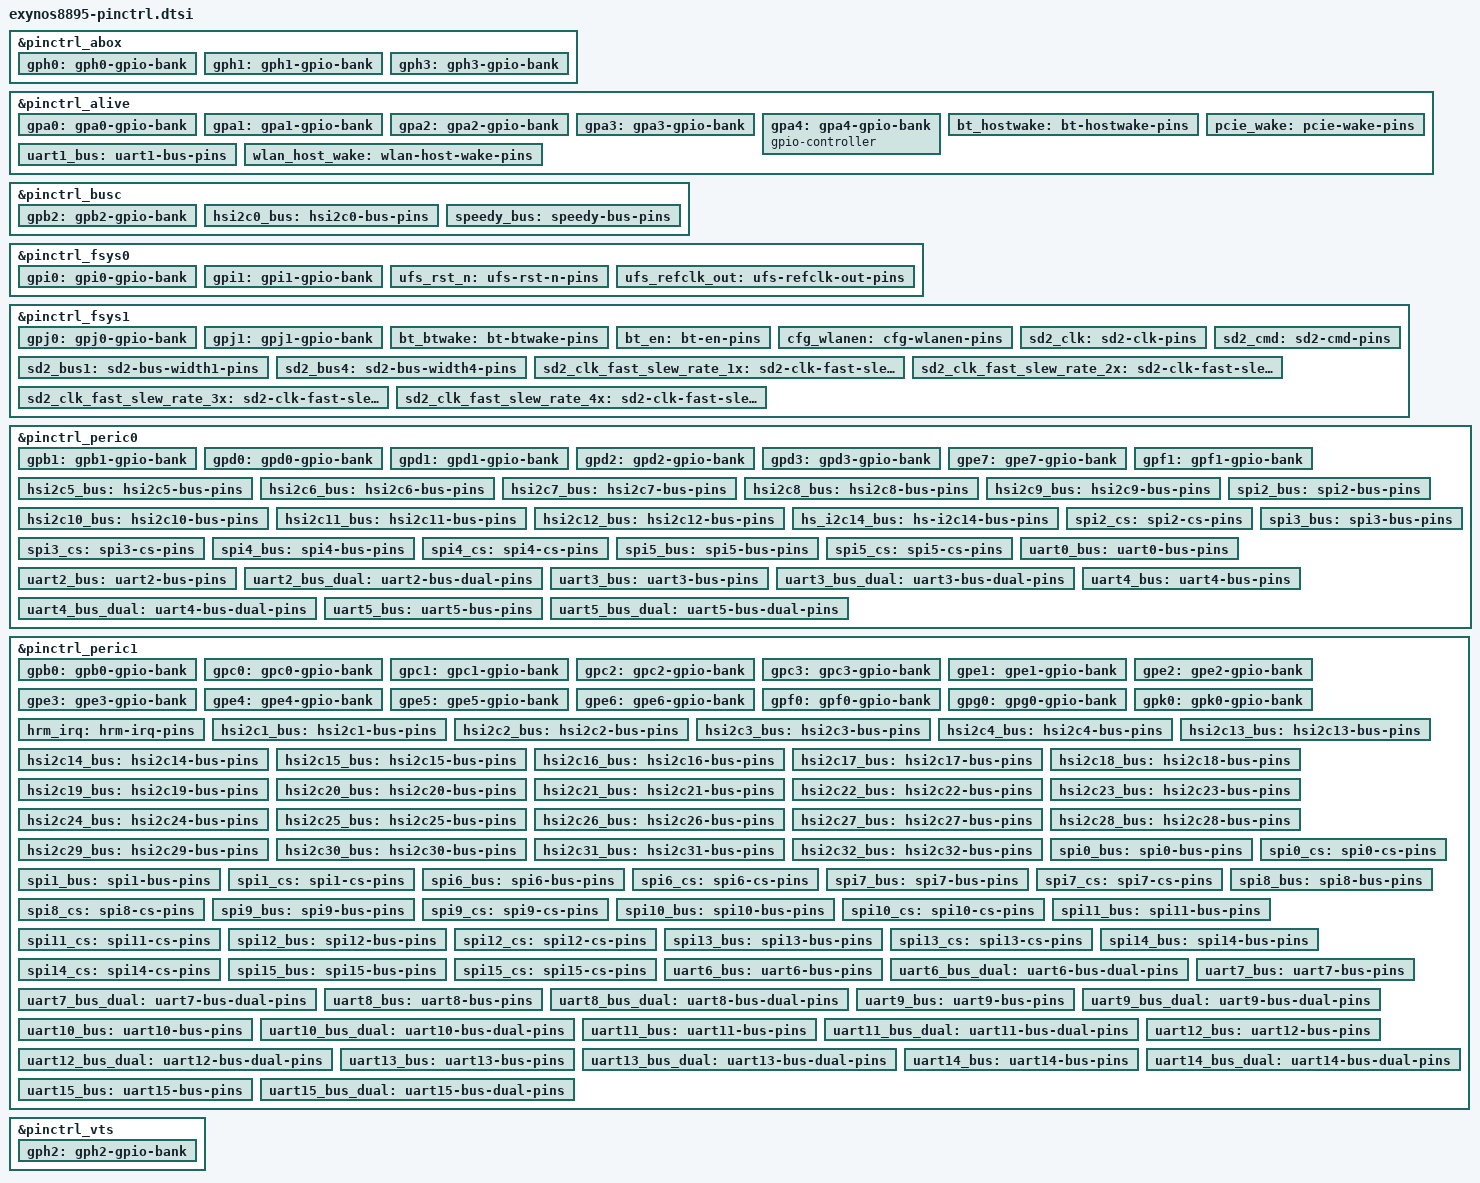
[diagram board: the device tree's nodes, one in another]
// SPDX-License-Identifier: GPL-2.0 OR BSD-3-Clause
/*
 * Samsung's Exynos 8895 SoC pin-mux and pin-config device tree source
 *
 * Copyright (c) 2024, Ivaylo Ivanov <ivo.ivanov.ivanov1@gmail.com>
 */

#include <dt-bindings/interrupt-controller/arm-gic.h>
#include "exynos-pinctrl.h"

&pinctrl_abox {
	gph0: gph0-gpio-bank {
		gpio-controller;
		#gpio-cells = <2>;

		interrupt-controller;
		#interrupt-cells = <2>;
	};

	gph1: gph1-gpio-bank {
		gpio-controller;
		#gpio-cells = <2>;

		interrupt-controller;
		#interrupt-cells = <2>;
	};

	gph3: gph3-gpio-bank {
		gpio-controller;
		#gpio-cells = <2>;

		interrupt-controller;
		#interrupt-cells = <2>;
	};
};

&pinctrl_alive {
	gpa0: gpa0-gpio-bank {
		gpio-controller;
		#gpio-cells = <2>;

		interrupt-controller;
		#interrupt-cells = <2>;
		interrupt-parent = <&gic>;
		interrupts = <GIC_SPI 0 IRQ_TYPE_LEVEL_HIGH>,
			     <GIC_SPI 1 IRQ_TYPE_LEVEL_HIGH>,
			     <GIC_SPI 2 IRQ_TYPE_LEVEL_HIGH>,
			     <GIC_SPI 3 IRQ_TYPE_LEVEL_HIGH>,
			     <GIC_SPI 4 IRQ_TYPE_LEVEL_HIGH>,
			     <GIC_SPI 5 IRQ_TYPE_LEVEL_HIGH>,
			     <GIC_SPI 6 IRQ_TYPE_LEVEL_HIGH>,
			     <GIC_SPI 7 IRQ_TYPE_LEVEL_HIGH>;
	};

	gpa1: gpa1-gpio-bank {
		gpio-controller;
		#gpio-cells = <2>;

		interrupt-controller;
		#interrupt-cells = <2>;
		interrupt-parent = <&gic>;
		interrupts = <GIC_SPI 8 IRQ_TYPE_LEVEL_HIGH>,
			     <GIC_SPI 9 IRQ_TYPE_LEVEL_HIGH>,
			     <GIC_SPI 10 IRQ_TYPE_LEVEL_HIGH>,
			     <GIC_SPI 11 IRQ_TYPE_LEVEL_HIGH>,
			     <GIC_SPI 12 IRQ_TYPE_LEVEL_HIGH>,
			     <GIC_SPI 13 IRQ_TYPE_LEVEL_HIGH>,
			     <GIC_SPI 14 IRQ_TYPE_LEVEL_HIGH>,
			     <GIC_SPI 15 IRQ_TYPE_LEVEL_HIGH>;
	};

	gpa2: gpa2-gpio-bank {
		gpio-controller;
		#gpio-cells = <2>;

		interrupt-controller;
		#interrupt-cells = <2>;
	};

	gpa3: gpa3-gpio-bank {
		gpio-controller;
		#gpio-cells = <2>;

		interrupt-controller;
		#interrupt-cells = <2>;
	};

	gpa4: gpa4-gpio-bank {
		gpio-controller;
		#gpio-cells = <2>;
	};

	bt_hostwake: bt-hostwake-pins {
		samsung,pins = "gpa2-3";
		samsung,pin-function = <EXYNOS_PIN_FUNC_INPUT>;
		samsung,pin-pud = <EXYNOS_PIN_PULL_NONE>;
		samsung,pin-con-pdn = <EXYNOS_PIN_PDN_INPUT>;
		samsung,pin-pud-pdn = <EXYNOS_PIN_PULL_NONE>;
	};

	pcie_wake: pcie-wake-pins {
		samsung,pins = "gpa3-3";
		samsung,pin-function = <EXYNOS_PIN_FUNC_INPUT>;
		samsung,pin-pud = <EXYNOS_PIN_PULL_NONE>;
	};

	uart1_bus: uart1-bus-pins {
		samsung,pins = "gpa4-4", "gpa4-3", "gpa4-2", "gpa4-1";
		samsung,pin-function = <EXYNOS_PIN_FUNC_2>;
		samsung,pin-pud = <EXYNOS_PIN_PULL_NONE>;
	};

	wlan_host_wake: wlan-host-wake-pins {
		  samsung,pins = "gpa0-7";
		  samsung,pin-function = <EXYNOS_PIN_FUNC_EINT>;
		  samsung,pin-pud = <EXYNOS_PIN_PULL_DOWN>;
		  samsung,pin-con-pdn = <EXYNOS_PIN_PDN_PREV>;
		  samsung,pin-pud-pdn = <EXYNOS_PIN_PULL_DOWN>;
	};
};

&pinctrl_busc {
	gpb2: gpb2-gpio-bank {
		gpio-controller;
		#gpio-cells = <2>;

		interrupt-controller;
		#interrupt-cells = <2>;
	};

	hsi2c0_bus: hsi2c0-bus-pins {
		samsung,pins = "gpb2-1", "gpb2-0";
		samsung,pin-function = <EXYNOS_PIN_FUNC_3>;
		samsung,pin-pud = <EXYNOS_PIN_PULL_UP>;
		samsung,pin-drv = <EXYNOS7_PIN_DRV_LV1>;
	};

	speedy_bus: speedy-bus-pins {
		samsung,pins = "gpb2-0";
		samsung,pin-function = <EXYNOS_PIN_FUNC_2>;
		samsung,pin-con-pdn = <EXYNOS_PIN_PDN_PREV>;
		samsung,pin-pud = <EXYNOS_PIN_PULL_UP>;
		samsung,pin-drv = <EXYNOS7_PIN_DRV_LV1>;
	};
};

&pinctrl_fsys0 {
	gpi0: gpi0-gpio-bank {
		gpio-controller;
		#gpio-cells = <2>;

		interrupt-controller;
		#interrupt-cells = <2>;
	};

	gpi1: gpi1-gpio-bank {
		gpio-controller;
		#gpio-cells = <2>;

		interrupt-controller;
		#interrupt-cells = <2>;
	};

	ufs_rst_n: ufs-rst-n-pins {
		samsung,pins = "gpi0-1";
		samsung,pin-function = <EXYNOS_PIN_FUNC_3>;
		samsung,pin-pud = <EXYNOS_PIN_PULL_NONE>;
		samsung,pin-con-pdn = <EXYNOS_PIN_PDN_PREV>;
	};

	ufs_refclk_out: ufs-refclk-out-pins {
		samsung,pins = "gpi0-0";
		samsung,pin-function = <EXYNOS_PIN_FUNC_3>;
		samsung,pin-pud = <EXYNOS_PIN_PULL_NONE>;
		samsung,pin-con-pdn = <EXYNOS_PIN_PDN_PREV>;
	};
};

&pinctrl_fsys1 {
	gpj0: gpj0-gpio-bank {
		gpio-controller;
		#gpio-cells = <2>;

		interrupt-controller;
		#interrupt-cells = <2>;
	};

	gpj1: gpj1-gpio-bank {
		gpio-controller;
		#gpio-cells = <2>;

		interrupt-controller;
		#interrupt-cells = <2>;
	};

	bt_btwake: bt-btwake-pins {
		samsung,pins = "gpj1-4";
		samsung,pin-function = <EXYNOS_PIN_FUNC_OUTPUT>;
		samsung,pin-pud = <EXYNOS_PIN_PULL_NONE>;
		samsung,pin-con-pdn = <EXYNOS_PIN_PDN_PREV>;
		samsung,pin-pud-pdn = <EXYNOS_PIN_PULL_NONE>;
	};

	bt_en: bt-en-pins {
		samsung,pins = "gpj1-7";
		samsung,pin-function = <EXYNOS_PIN_FUNC_OUTPUT>;
		samsung,pin-pud = <EXYNOS_PIN_PULL_NONE>;
		samsung,pin-con-pdn = <EXYNOS_PIN_PDN_PREV>;
		samsung,pin-pud-pdn = <EXYNOS_PIN_PULL_NONE>;
	};

	cfg_wlanen: cfg-wlanen-pins {
		samsung,pins = "gpj1-3";
		samsung,pin-function = <EXYNOS_PIN_FUNC_OUTPUT>;
		samsung,pin-pud = <EXYNOS_PIN_PULL_NONE>;
		samsung,pin-drv = <EXYNOS7_PIN_DRV_LV4>;
		samsung,pin-con-pdn = <EXYNOS_PIN_PDN_PREV>;
	};

	sd2_clk: sd2-clk-pins {
		samsung,pins = "gpj0-0";
		samsung,pin-function = <EXYNOS_PIN_FUNC_2>;
		samsung,pin-pud = <EXYNOS_PIN_PULL_NONE>;
		samsung,pin-drv = <EXYNOS7_PIN_DRV_LV2>;
	};

	sd2_cmd: sd2-cmd-pins {
		samsung,pins = "gpj0-1";
		samsung,pin-function = <EXYNOS_PIN_FUNC_2>;
		samsung,pin-pud = <EXYNOS_PIN_PULL_NONE>;
		samsung,pin-drv = <EXYNOS7_PIN_DRV_LV3>;
	};

	sd2_bus1: sd2-bus-width1-pins {
		samsung,pins = "gpj0-2";
		samsung,pin-function = <EXYNOS_PIN_FUNC_2>;
		samsung,pin-pud = <EXYNOS_PIN_PULL_NONE>;
		samsung,pin-drv = <EXYNOS7_PIN_DRV_LV3>;
	};

	sd2_bus4: sd2-bus-width4-pins {
		samsung,pins = "gpj0-3", "gpj0-4", "gpj0-5";
		samsung,pin-function = <EXYNOS_PIN_FUNC_2>;
		samsung,pin-pud = <EXYNOS_PIN_PULL_NONE>;
		samsung,pin-drv = <EXYNOS7_PIN_DRV_LV3>;
	};

	/* For Drive strength swapping */
	sd2_clk_fast_slew_rate_1x: sd2-clk-fast-slew-rate-1x-pins {
		samsung,pins = "gpj0-0";
		samsung,pin-function = <EXYNOS_PIN_FUNC_2>;
		samsung,pin-pud = <EXYNOS_PIN_PULL_NONE>;
		samsung,pin-drv = <EXYNOS7_PIN_DRV_LV1>;
	};

	sd2_clk_fast_slew_rate_2x: sd2-clk-fast-slew-rate-2x-pins {
		samsung,pins = "gpj0-0";
		samsung,pin-function = <EXYNOS_PIN_FUNC_2>;
		samsung,pin-pud = <EXYNOS_PIN_PULL_NONE>;
		samsung,pin-drv = <EXYNOS7_PIN_DRV_LV3>;
	};

	sd2_clk_fast_slew_rate_3x: sd2-clk-fast-slew-rate-3x-pins {
		samsung,pins = "gpj0-0";
		samsung,pin-function = <EXYNOS_PIN_FUNC_2>;
		samsung,pin-pud = <EXYNOS_PIN_PULL_NONE>;
		samsung,pin-drv = <EXYNOS7_PIN_DRV_LV2>;
	};

	sd2_clk_fast_slew_rate_4x: sd2-clk-fast-slew-rate-4x-pins {
		samsung,pins = "gpj0-0";
		samsung,pin-function = <EXYNOS_PIN_FUNC_2>;
		samsung,pin-pud = <EXYNOS_PIN_PULL_NONE>;
		samsung,pin-drv = <EXYNOS7_PIN_DRV_LV4>;
	};
};

&pinctrl_peric0 {
	gpb1: gpb1-gpio-bank {
		gpio-controller;
		#gpio-cells = <2>;

		interrupt-controller;
		#interrupt-cells = <2>;
	};

	gpd0: gpd0-gpio-bank {
		gpio-controller;
		#gpio-cells = <2>;

		interrupt-controller;
		#interrupt-cells = <2>;
	};

	gpd1: gpd1-gpio-bank {
		gpio-controller;
		#gpio-cells = <2>;

		interrupt-controller;
		#interrupt-cells = <2>;
	};

	gpd2: gpd2-gpio-bank {
		gpio-controller;
		#gpio-cells = <2>;

		interrupt-controller;
		#interrupt-cells = <2>;
	};

	gpd3: gpd3-gpio-bank {
		gpio-controller;
		#gpio-cells = <2>;

		interrupt-controller;
		#interrupt-cells = <2>;
	};

	gpe7: gpe7-gpio-bank {
		gpio-controller;
		#gpio-cells = <2>;

		interrupt-controller;
		#interrupt-cells = <2>;
	};

	gpf1: gpf1-gpio-bank {
		gpio-controller;
		#gpio-cells = <2>;

		interrupt-controller;
		#interrupt-cells = <2>;
	};

	hsi2c5_bus: hsi2c5-bus-pins {
		samsung,pins = "gpd1-1", "gpd1-0";
		samsung,pin-function = <EXYNOS_PIN_FUNC_2>;
		samsung,pin-pud = <EXYNOS_PIN_PULL_NONE>;
		samsung,pin-drv = <EXYNOS7_PIN_DRV_LV1>;
	};

	hsi2c6_bus: hsi2c6-bus-pins {
		samsung,pins = "gpd1-3", "gpd1-2";
		samsung,pin-function = <EXYNOS_PIN_FUNC_2>;
		samsung,pin-pud = <EXYNOS_PIN_PULL_NONE>;
		samsung,pin-drv = <EXYNOS7_PIN_DRV_LV1>;
	};

	hsi2c7_bus: hsi2c7-bus-pins {
		samsung,pins = "gpd1-5", "gpd1-4";
		samsung,pin-function = <EXYNOS_PIN_FUNC_2>;
		samsung,pin-pud = <EXYNOS_PIN_PULL_NONE>;
		samsung,pin-drv = <EXYNOS7_PIN_DRV_LV1>;
	};

	hsi2c8_bus: hsi2c8-bus-pins {
		samsung,pins = "gpd1-7", "gpd1-6";
		samsung,pin-function = <EXYNOS_PIN_FUNC_2>;
		samsung,pin-pud = <EXYNOS_PIN_PULL_NONE>;
		samsung,pin-drv = <EXYNOS7_PIN_DRV_LV1>;
	};

	hsi2c9_bus: hsi2c9-bus-pins {
		samsung,pins = "gpd2-1", "gpd2-0";
		samsung,pin-function = <EXYNOS_PIN_FUNC_2>;
		samsung,pin-pud = <EXYNOS_PIN_PULL_NONE>;
		samsung,pin-drv = <EXYNOS7_PIN_DRV_LV1>;
	};

	hsi2c10_bus: hsi2c10-bus-pins {
		samsung,pins = "gpd2-3", "gpd2-2";
		samsung,pin-function = <EXYNOS_PIN_FUNC_2>;
		samsung,pin-pud = <EXYNOS_PIN_PULL_NONE>;
		samsung,pin-drv = <EXYNOS7_PIN_DRV_LV1>;
	};

	hsi2c11_bus: hsi2c11-bus-pins {
		samsung,pins = "gpd3-1", "gpd3-0";
		samsung,pin-function = <EXYNOS_PIN_FUNC_2>;
		samsung,pin-pud = <EXYNOS_PIN_PULL_NONE>;
		samsung,pin-drv = <EXYNOS7_PIN_DRV_LV1>;
	};

	hsi2c12_bus: hsi2c12-bus-pins {
		samsung,pins = "gpd3-3", "gpd3-2";
		samsung,pin-function = <EXYNOS_PIN_FUNC_2>;
		samsung,pin-pud = <EXYNOS_PIN_PULL_NONE>;
		samsung,pin-drv = <EXYNOS7_PIN_DRV_LV1>;
	};

	hs_i2c14_bus: hs-i2c14-bus-pins {
		samsung,pins = "gpe6-3", "gpe6-2";
		samsung,pin-function = <EXYNOS_PIN_FUNC_2>;
		samsung,pin-pud = <EXYNOS_PIN_PULL_NONE>;
		samsung,pin-drv = <EXYNOS7_PIN_DRV_LV2>;
	};

	spi2_bus: spi2-bus-pins {
		samsung,pins = "gpd1-3", "gpd1-2", "gpd1-1", "gpd1-0";
		samsung,pin-function = <EXYNOS_PIN_FUNC_2>;
		samsung,pin-pud = <EXYNOS_PIN_PULL_UP>;
		samsung,pin-drv = <EXYNOS7_PIN_DRV_LV2>;
	};

	spi2_cs: spi2-cs-pins {
		samsung,pins = "gpd1-2";
		samsung,pin-function = <EXYNOS_PIN_FUNC_OUTPUT>;
		samsung,pin-pud = <EXYNOS_PIN_PULL_UP>;
		samsung,pin-drv = <EXYNOS7_PIN_DRV_LV1>;
	};

	spi3_bus: spi3-bus-pins {
		samsung,pins = "gpd1-7", "gpd1-5", "gpd1-4";
		samsung,pin-function = <EXYNOS_PIN_FUNC_2>;
		samsung,pin-pud = <EXYNOS_PIN_PULL_NONE>;
		samsung,pin-drv = <EXYNOS7_PIN_DRV_LV1>;
	};

	spi3_cs: spi3-cs-pins {
		samsung,pins = "gpd1-6";
		samsung,pin-function = <EXYNOS_PIN_FUNC_OUTPUT>;
		samsung,pin-pud = <EXYNOS_PIN_PULL_UP>;
		samsung,pin-drv = <EXYNOS7_PIN_DRV_LV1>;
	};

	spi4_bus: spi4-bus-pins {
		samsung,pins = "gpd2-3", "gpd2-1", "gpd2-0";
		samsung,pin-function = <EXYNOS_PIN_FUNC_2>;
		samsung,pin-pud = <EXYNOS_PIN_PULL_UP>;
		samsung,pin-drv = <EXYNOS7_PIN_DRV_LV1>;
	};

	spi4_cs: spi4-cs-pins {
		samsung,pins = "gpd2-2";
		samsung,pin-function = <EXYNOS_PIN_FUNC_OUTPUT>;
		samsung,pin-pud = <EXYNOS_PIN_PULL_UP>;
		samsung,pin-drv = <EXYNOS7_PIN_DRV_LV1>;
	};

	spi5_bus: spi5-bus-pins {
		samsung,pins = "gpd3-3", "gpd3-1", "gpd3-0";
		samsung,pin-function = <EXYNOS_PIN_FUNC_2>;
		samsung,pin-pud = <EXYNOS_PIN_PULL_UP>;
		samsung,pin-drv = <EXYNOS7_PIN_DRV_LV1>;
	};

	spi5_cs: spi5-cs-pins {
		samsung,pins = "gpd3-2";
		samsung,pin-function = <EXYNOS_PIN_FUNC_OUTPUT>;
		samsung,pin-pud = <EXYNOS_PIN_PULL_UP>;
		samsung,pin-drv = <EXYNOS7_PIN_DRV_LV1>;
	};

	uart0_bus: uart0-bus-pins {
		samsung,pins = "gpd0-7", "gpd0-6";
		samsung,pin-function = <EXYNOS_PIN_FUNC_3>;
		samsung,pin-pud = <EXYNOS_PIN_PULL_NONE>;
	};

	uart2_bus: uart2-bus-pins {
		samsung,pins = "gpd1-3", "gpd1-2", "gpd1-1", "gpd1-0";
		samsung,pin-function = <EXYNOS_PIN_FUNC_2>;
		samsung,pin-pud = <EXYNOS_PIN_PULL_NONE>;
	};

	uart2_bus_dual: uart2-bus-dual-pins {
		samsung,pins = "gpd1-1", "gpd1-0";
		samsung,pin-function = <EXYNOS_PIN_FUNC_2>;
		samsung,pin-pud = <EXYNOS_PIN_PULL_NONE>;
	};

	uart3_bus: uart3-bus-pins {
		samsung,pins = "gpd1-7", "gpd1-6", "gpd1-5", "gpd1-4";
		samsung,pin-function = <EXYNOS_PIN_FUNC_2>;
		samsung,pin-pud = <EXYNOS_PIN_PULL_NONE>;
	};

	uart3_bus_dual: uart3-bus-dual-pins {
		samsung,pins = "gpd1-5", "gpd1-4";
		samsung,pin-function = <EXYNOS_PIN_FUNC_2>;
		samsung,pin-pud = <EXYNOS_PIN_PULL_NONE>;
	};

	uart4_bus: uart4-bus-pins {
		samsung,pins = "gpd2-3", "gpd2-2", "gpd2-1", "gpd2-0";
		samsung,pin-function = <EXYNOS_PIN_FUNC_2>;
		samsung,pin-pud = <EXYNOS_PIN_PULL_NONE>;
	};

	uart4_bus_dual: uart4-bus-dual-pins {
		samsung,pins = "gpd2-1", "gpd2-0";
		samsung,pin-function = <EXYNOS_PIN_FUNC_2>;
		samsung,pin-pud = <EXYNOS_PIN_PULL_NONE>;
	};

	uart5_bus: uart5-bus-pins {
		samsung,pins = "gpd3-3", "gpd3-2", "gpd3-1", "gpd3-0";
		samsung,pin-function = <EXYNOS_PIN_FUNC_2>;
		samsung,pin-pud = <EXYNOS_PIN_PULL_NONE>;
	};

	uart5_bus_dual: uart5-bus-dual-pins {
		samsung,pins = "gpd3-1", "gpd3-0";
		samsung,pin-function = <EXYNOS_PIN_FUNC_2>;
		samsung,pin-pud = <EXYNOS_PIN_PULL_NONE>;
	};
};

&pinctrl_peric1 {
	gpb0: gpb0-gpio-bank {
		gpio-controller;
		#gpio-cells = <2>;

		interrupt-controller;
		#interrupt-cells = <2>;
	};

	gpc0: gpc0-gpio-bank {
		gpio-controller;
		#gpio-cells = <2>;

		interrupt-controller;
		#interrupt-cells = <2>;
	};

	gpc1: gpc1-gpio-bank {
		gpio-controller;
		#gpio-cells = <2>;

		interrupt-controller;
		#interrupt-cells = <2>;
	};

	gpc2: gpc2-gpio-bank {
		gpio-controller;
		#gpio-cells = <2>;

		interrupt-controller;
		#interrupt-cells = <2>;
	};

	gpc3: gpc3-gpio-bank {
		gpio-controller;
		#gpio-cells = <2>;

		interrupt-controller;
		#interrupt-cells = <2>;
	};

	gpe1: gpe1-gpio-bank {
		gpio-controller;
		#gpio-cells = <2>;

		interrupt-controller;
		#interrupt-cells = <2>;
	};

	gpe2: gpe2-gpio-bank {
		gpio-controller;
		#gpio-cells = <2>;

		interrupt-controller;
		#interrupt-cells = <2>;
	};

	gpe3: gpe3-gpio-bank {
		gpio-controller;
		#gpio-cells = <2>;

		interrupt-controller;
		#interrupt-cells = <2>;
	};

	gpe4: gpe4-gpio-bank {
		gpio-controller;
		#gpio-cells = <2>;

		interrupt-controller;
		#interrupt-cells = <2>;
	};

	gpe5: gpe5-gpio-bank {
		gpio-controller;
		#gpio-cells = <2>;

		interrupt-controller;
		#interrupt-cells = <2>;
	};

	gpe6: gpe6-gpio-bank {
		gpio-controller;
		#gpio-cells = <2>;

		interrupt-controller;
		#interrupt-cells = <2>;
	};

	gpf0: gpf0-gpio-bank {
		gpio-controller;
		#gpio-cells = <2>;

		interrupt-controller;
		#interrupt-cells = <2>;
	};

	gpg0: gpg0-gpio-bank {
		gpio-controller;
		#gpio-cells = <2>;

		interrupt-controller;
		#interrupt-cells = <2>;
	};

	gpk0: gpk0-gpio-bank {
		gpio-controller;
		#gpio-cells = <2>;

		interrupt-controller;
		#interrupt-cells = <2>;
	};

	hrm_irq: hrm-irq-pins {
		samsung,pins = "gpe6-6";
		samsung,pin-function = <EXYNOS_PIN_FUNC_INPUT>;
		samsung,pin-pud = <EXYNOS_PIN_PULL_NONE>;
		samsung,pin-drv = <EXYNOS7_PIN_DRV_LV4>;
	};

	hsi2c1_bus: hsi2c1-bus-pins {
		samsung,pins = "gpc2-1", "gpc2-0";
		samsung,pin-function = <EXYNOS_PIN_FUNC_2>;
		samsung,pin-pud = <EXYNOS_PIN_PULL_NONE>;
		samsung,pin-drv = <EXYNOS7_PIN_DRV_LV1>;
	};

	hsi2c2_bus: hsi2c2-bus-pins {
		samsung,pins = "gpc2-3", "gpc2-2";
		samsung,pin-function = <EXYNOS_PIN_FUNC_2>;
		samsung,pin-pud = <EXYNOS_PIN_PULL_NONE>;
		samsung,pin-drv = <EXYNOS7_PIN_DRV_LV4>;
	};

	hsi2c3_bus: hsi2c3-bus-pins {
		samsung,pins = "gpc2-5", "gpc2-4";
		samsung,pin-function = <EXYNOS_PIN_FUNC_2>;
		samsung,pin-pud = <EXYNOS_PIN_PULL_NONE>;
		samsung,pin-drv = <EXYNOS7_PIN_DRV_LV1>;
	};

	hsi2c4_bus: hsi2c4-bus-pins {
		samsung,pins = "gpc2-7", "gpc2-6";
		samsung,pin-function = <EXYNOS_PIN_FUNC_2>;
		samsung,pin-pud = <EXYNOS_PIN_PULL_NONE>;
		samsung,pin-drv = <EXYNOS7_PIN_DRV_LV1>;
	};

	hsi2c13_bus: hsi2c13-bus-pins {
		samsung,pins = "gpe5-1", "gpe5-0";
		samsung,pin-function = <EXYNOS_PIN_FUNC_2>;
		samsung,pin-pud = <EXYNOS_PIN_PULL_NONE>;
		samsung,pin-drv = <EXYNOS7_PIN_DRV_LV1>;
	};

	hsi2c14_bus: hsi2c14-bus-pins {
		samsung,pins = "gpe5-3", "gpe5-2";
		samsung,pin-function = <EXYNOS_PIN_FUNC_2>;
		samsung,pin-pud = <EXYNOS_PIN_PULL_NONE>;
		samsung,pin-drv = <EXYNOS7_PIN_DRV_LV1>;
	};

	hsi2c15_bus: hsi2c15-bus-pins {
		samsung,pins = "gpe1-1", "gpe1-0";
		samsung,pin-function = <EXYNOS_PIN_FUNC_2>;
		samsung,pin-pud = <EXYNOS_PIN_PULL_NONE>;
		samsung,pin-drv = <EXYNOS7_PIN_DRV_LV1>;
	};

	hsi2c16_bus: hsi2c16-bus-pins {
		samsung,pins = "gpe1-3", "gpe1-2";
		samsung,pin-function = <EXYNOS_PIN_FUNC_2>;
		samsung,pin-pud = <EXYNOS_PIN_PULL_NONE>;
		samsung,pin-drv = <EXYNOS7_PIN_DRV_LV1>;
	};

	hsi2c17_bus: hsi2c17-bus-pins {
		samsung,pins = "gpe1-5", "gpe1-4";
		samsung,pin-function = <EXYNOS_PIN_FUNC_2>;
		samsung,pin-pud = <EXYNOS_PIN_PULL_NONE>;
		samsung,pin-drv = <EXYNOS7_PIN_DRV_LV1>;
	};

	hsi2c18_bus: hsi2c18-bus-pins {
		samsung,pins = "gpe1-7", "gpe1-6";
		samsung,pin-function = <EXYNOS_PIN_FUNC_2>;
		samsung,pin-pud = <EXYNOS_PIN_PULL_NONE>;
		samsung,pin-drv = <EXYNOS7_PIN_DRV_LV1>;
	};

	hsi2c19_bus: hsi2c19-bus-pins {
		samsung,pins = "gpe2-1", "gpe2-0";
		samsung,pin-function = <EXYNOS_PIN_FUNC_2>;
		samsung,pin-pud = <EXYNOS_PIN_PULL_NONE>;
		samsung,pin-drv = <EXYNOS7_PIN_DRV_LV1>;
	};

	hsi2c20_bus: hsi2c20-bus-pins {
		samsung,pins = "gpe2-3", "gpe2-2";
		samsung,pin-function = <EXYNOS_PIN_FUNC_2>;
		samsung,pin-pud = <EXYNOS_PIN_PULL_NONE>;
		samsung,pin-drv = <EXYNOS7_PIN_DRV_LV1>;
	};

	hsi2c21_bus: hsi2c21-bus-pins {
		samsung,pins = "gpe2-5", "gpe2-4";
		samsung,pin-function = <EXYNOS_PIN_FUNC_2>;
		samsung,pin-pud = <EXYNOS_PIN_PULL_NONE>;
		samsung,pin-drv = <EXYNOS7_PIN_DRV_LV1>;
	};

	hsi2c22_bus: hsi2c22-bus-pins {
		samsung,pins = "gpe2-7", "gpe2-6";
		samsung,pin-function = <EXYNOS_PIN_FUNC_2>;
		samsung,pin-pud = <EXYNOS_PIN_PULL_NONE>;
		samsung,pin-drv = <EXYNOS7_PIN_DRV_LV1>;
	};

	hsi2c23_bus: hsi2c23-bus-pins {
		samsung,pins = "gpe3-1", "gpe3-0";
		samsung,pin-function = <EXYNOS_PIN_FUNC_2>;
		samsung,pin-pud = <EXYNOS_PIN_PULL_NONE>;
		samsung,pin-drv = <EXYNOS7_PIN_DRV_LV1>;
	};

	hsi2c24_bus: hsi2c24-bus-pins {
		samsung,pins = "gpe3-3", "gpe3-2";
		samsung,pin-function = <EXYNOS_PIN_FUNC_2>;
		samsung,pin-pud = <EXYNOS_PIN_PULL_NONE>;
		samsung,pin-drv = <EXYNOS7_PIN_DRV_LV1>;
	};

	hsi2c25_bus: hsi2c25-bus-pins {
		samsung,pins = "gpe3-5", "gpe3-4";
		samsung,pin-function = <EXYNOS_PIN_FUNC_2>;
		samsung,pin-pud = <EXYNOS_PIN_PULL_NONE>;
		samsung,pin-drv = <EXYNOS7_PIN_DRV_LV1>;
	};

	hsi2c26_bus: hsi2c26-bus-pins {
		samsung,pins = "gpe3-7", "gpe3-6";
		samsung,pin-function = <EXYNOS_PIN_FUNC_2>;
		samsung,pin-pud = <EXYNOS_PIN_PULL_NONE>;
		samsung,pin-drv = <EXYNOS7_PIN_DRV_LV1>;
	};

	hsi2c27_bus: hsi2c27-bus-pins {
		samsung,pins = "gpe4-1", "gpe4-0";
		samsung,pin-function = <EXYNOS_PIN_FUNC_2>;
		samsung,pin-pud = <EXYNOS_PIN_PULL_NONE>;
		samsung,pin-drv = <EXYNOS7_PIN_DRV_LV1>;
	};

	hsi2c28_bus: hsi2c28-bus-pins {
		samsung,pins = "gpe4-3", "gpe4-2";
		samsung,pin-function = <EXYNOS_PIN_FUNC_2>;
		samsung,pin-pud = <EXYNOS_PIN_PULL_NONE>;
		samsung,pin-drv = <EXYNOS7_PIN_DRV_LV1>;
	};

	hsi2c29_bus: hsi2c29-bus-pins {
		samsung,pins = "gpe4-5", "gpe4-4";
		samsung,pin-function = <EXYNOS_PIN_FUNC_2>;
		samsung,pin-pud = <EXYNOS_PIN_PULL_NONE>;
		samsung,pin-drv = <EXYNOS7_PIN_DRV_LV1>;
	};

	hsi2c30_bus: hsi2c30-bus-pins {
		samsung,pins = "gpe4-7", "gpe4-6";
		samsung,pin-function = <EXYNOS_PIN_FUNC_2>;
		samsung,pin-pud = <EXYNOS_PIN_PULL_NONE>;
		samsung,pin-drv = <EXYNOS7_PIN_DRV_LV2>;
	};

	hsi2c31_bus: hsi2c31-bus-pins {
		samsung,pins = "gpe5-5", "gpe5-4";
		samsung,pin-function = <EXYNOS_PIN_FUNC_2>;
		samsung,pin-pud = <EXYNOS_PIN_PULL_NONE>;
		samsung,pin-drv = <EXYNOS7_PIN_DRV_LV1>;
	};

	hsi2c32_bus: hsi2c32-bus-pins {
		samsung,pins = "gpe5-7", "gpe5-6";
		samsung,pin-function = <EXYNOS_PIN_FUNC_2>;
		samsung,pin-pud = <EXYNOS_PIN_PULL_NONE>;
		samsung,pin-drv = <EXYNOS7_PIN_DRV_LV1>;
	};

	spi0_bus: spi0-bus-pins {
		samsung,pins = "gpc3-3", "gpc3-2", "gpc3-0";
		samsung,pin-function = <EXYNOS_PIN_FUNC_2>;
		samsung,pin-pud = <EXYNOS_PIN_PULL_UP>;
		samsung,pin-drv = <EXYNOS7_PIN_DRV_LV1>;
	};

	spi0_cs: spi0-cs-pins {
		samsung,pins = "gpc3-1";
		samsung,pin-function = <EXYNOS_PIN_FUNC_OUTPUT>;
		samsung,pin-pud = <EXYNOS_PIN_PULL_UP>;
		samsung,pin-drv = <EXYNOS7_PIN_DRV_LV1>;
	};

	spi1_bus: spi1-bus-pins {
		samsung,pins = "gpc3-7", "gpc3-6", "gpc3-4";
		samsung,pin-function = <EXYNOS_PIN_FUNC_2>;
		samsung,pin-pud = <EXYNOS_PIN_PULL_UP>;
		samsung,pin-drv = <EXYNOS7_PIN_DRV_LV1>;
	};

	spi1_cs: spi1-cs-pins {
		samsung,pins = "gpc3-5";
		samsung,pin-function = <EXYNOS_PIN_FUNC_OUTPUT>;
		samsung,pin-pud = <EXYNOS_PIN_PULL_UP>;
		samsung,pin-drv = <EXYNOS7_PIN_DRV_LV1>;
	};

	spi6_bus: spi6-bus-pins {
		samsung,pins = "gpe5-3", "gpe5-1", "gpe5-0";
		samsung,pin-function = <EXYNOS_PIN_FUNC_2>;
		samsung,pin-pud = <EXYNOS_PIN_PULL_UP>;
		samsung,pin-drv = <EXYNOS7_PIN_DRV_LV1>;
	};

	spi6_cs: spi6-cs-pins {
		samsung,pins = "gpe5-2";
		samsung,pin-function = <EXYNOS_PIN_FUNC_OUTPUT>;
		samsung,pin-pud = <EXYNOS_PIN_PULL_UP>;
		samsung,pin-drv = <EXYNOS7_PIN_DRV_LV1>;
	};

	spi7_bus: spi7-bus-pins {
		samsung,pins = "gpe1-3", "gpe1-1", "gpe1-0";
		samsung,pin-function = <EXYNOS_PIN_FUNC_2>;
		samsung,pin-pud = <EXYNOS_PIN_PULL_UP>;
		samsung,pin-drv = <EXYNOS7_PIN_DRV_LV1>;
	};

	spi7_cs: spi7-cs-pins {
		samsung,pins = "gpe1-2";
		samsung,pin-function = <EXYNOS_PIN_FUNC_OUTPUT>;
		samsung,pin-pud = <EXYNOS_PIN_PULL_UP>;
		samsung,pin-drv = <EXYNOS7_PIN_DRV_LV1>;
	};

	spi8_bus: spi8-bus-pins {
		samsung,pins = "gpe1-7", "gpe1-5", "gpe1-4";
		samsung,pin-function = <EXYNOS_PIN_FUNC_2>;
		samsung,pin-pud = <EXYNOS_PIN_PULL_NONE>;
		samsung,pin-drv = <EXYNOS7_PIN_DRV_LV1>;
	};

	spi8_cs: spi8-cs-pins {
		samsung,pins = "gpe1-6";
		samsung,pin-function = <EXYNOS_PIN_FUNC_OUTPUT>;
		samsung,pin-pud = <EXYNOS_PIN_PULL_NONE>;
		samsung,pin-drv = <EXYNOS7_PIN_DRV_LV1>;
	};

	spi9_bus: spi9-bus-pins {
		samsung,pins = "gpe2-3", "gpe2-1", "gpe2-0";
		samsung,pin-function = <EXYNOS_PIN_FUNC_2>;
		samsung,pin-pud = <EXYNOS_PIN_PULL_UP>;
		samsung,pin-drv = <EXYNOS7_PIN_DRV_LV1>;
	};

	spi9_cs: spi9-cs-pins {
		samsung,pins = "gpe2-2";
		samsung,pin-function = <EXYNOS_PIN_FUNC_OUTPUT>;
		samsung,pin-pud = <EXYNOS_PIN_PULL_UP>;
		samsung,pin-drv = <EXYNOS7_PIN_DRV_LV1>;
	};

	spi10_bus: spi10-bus-pins {
		samsung,pins = "gpe2-7", "gpe2-5", "gpe2-4";
		samsung,pin-function = <EXYNOS_PIN_FUNC_2>;
		samsung,pin-pud = <EXYNOS_PIN_PULL_NONE>;
		samsung,pin-drv = <EXYNOS7_PIN_DRV_LV1>;
	};

	spi10_cs: spi10-cs-pins {
		samsung,pins = "gpe2-6";
		samsung,pin-function = <EXYNOS_PIN_FUNC_OUTPUT>;
		samsung,pin-pud = <EXYNOS_PIN_PULL_UP>;
		samsung,pin-drv = <EXYNOS7_PIN_DRV_LV1>;
	};

	spi11_bus: spi11-bus-pins {
		samsung,pins = "gpe3-3", "gpe3-1", "gpe3-0";
		samsung,pin-function = <EXYNOS_PIN_FUNC_2>;
		samsung,pin-pud = <EXYNOS_PIN_PULL_UP>;
		samsung,pin-drv = <EXYNOS7_PIN_DRV_LV1>;
	};

	spi11_cs: spi11-cs-pins {
		samsung,pins = "gpe3-2";
		samsung,pin-function = <EXYNOS_PIN_FUNC_OUTPUT>;
		samsung,pin-pud = <EXYNOS_PIN_PULL_UP>;
		samsung,pin-drv = <EXYNOS7_PIN_DRV_LV1>;
	};

	spi12_bus: spi12-bus-pins {
		samsung,pins = "gpe3-7", "gpe3-5", "gpe3-4";
		samsung,pin-function = <EXYNOS_PIN_FUNC_2>;
		samsung,pin-pud = <EXYNOS_PIN_PULL_UP>;
		samsung,pin-drv = <EXYNOS7_PIN_DRV_LV1>;
	};

	spi12_cs: spi12-cs-pins {
		samsung,pins = "gpe3-6";
		samsung,pin-function = <EXYNOS_PIN_FUNC_OUTPUT>;
		samsung,pin-pud = <EXYNOS_PIN_PULL_UP>;
		samsung,pin-drv = <EXYNOS7_PIN_DRV_LV1>;
	};

	spi13_bus: spi13-bus-pins {
		samsung,pins = "gpe4-3", "gpe4-1", "gpe4-0";
		samsung,pin-function = <EXYNOS_PIN_FUNC_2>;
		samsung,pin-pud = <EXYNOS_PIN_PULL_UP>;
		samsung,pin-drv = <EXYNOS7_PIN_DRV_LV1>;
	};

	spi13_cs: spi13-cs-pins {
		samsung,pins = "gpe4-2";
		samsung,pin-function = <EXYNOS_PIN_FUNC_OUTPUT>;
		samsung,pin-pud = <EXYNOS_PIN_PULL_UP>;
		samsung,pin-drv = <EXYNOS7_PIN_DRV_LV1>;
	};

	spi14_bus: spi14-bus-pins {
		samsung,pins = "gpe4-7", "gpe4-5", "gpe4-4";
		samsung,pin-function = <EXYNOS_PIN_FUNC_2>;
		samsung,pin-pud = <EXYNOS_PIN_PULL_UP>;
		samsung,pin-drv = <EXYNOS7_PIN_DRV_LV1>;
	};

	spi14_cs: spi14-cs-pins {
		samsung,pins = "gpe4-6";
		samsung,pin-function = <EXYNOS_PIN_FUNC_OUTPUT>;
		samsung,pin-pud = <EXYNOS_PIN_PULL_UP>;
		samsung,pin-drv = <EXYNOS7_PIN_DRV_LV1>;
	};

	spi15_bus: spi15-bus-pins {
		samsung,pins = "gpe5-7", "gpe5-5", "gpe5-4";
		samsung,pin-function = <EXYNOS_PIN_FUNC_2>;
		samsung,pin-pud = <EXYNOS_PIN_PULL_UP>;
		samsung,pin-drv = <EXYNOS7_PIN_DRV_LV1>;
	};

	spi15_cs: spi15-cs-pins {
		samsung,pins = "gpe5-6";
		samsung,pin-function = <EXYNOS_PIN_FUNC_OUTPUT>;
		samsung,pin-pud = <EXYNOS_PIN_PULL_UP>;
		samsung,pin-drv = <EXYNOS7_PIN_DRV_LV1>;
	};

	uart6_bus: uart6-bus-pins {
		samsung,pins = "gpe5-3", "gpe5-2", "gpe5-1", "gpe5-0";
		samsung,pin-function = <EXYNOS_PIN_FUNC_2>;
		samsung,pin-pud = <EXYNOS_PIN_PULL_NONE>;
	};

	uart6_bus_dual: uart6-bus-dual-pins {
		samsung,pins = "gpe5-1", "gpe5-0";
		samsung,pin-function = <EXYNOS_PIN_FUNC_2>;
		samsung,pin-pud = <EXYNOS_PIN_PULL_NONE>;
	};

	uart7_bus: uart7-bus-pins {
		samsung,pins = "gpe1-3", "gpe1-2", "gpe1-1", "gpe1-0";
		samsung,pin-function = <EXYNOS_PIN_FUNC_2>;
		samsung,pin-pud = <EXYNOS_PIN_PULL_NONE>;
	};

	uart7_bus_dual: uart7-bus-dual-pins {
		samsung,pins = "gpe1-1", "gpe1-0";
		samsung,pin-function = <EXYNOS_PIN_FUNC_2>;
		samsung,pin-pud = <EXYNOS_PIN_PULL_NONE>;
	};

	uart8_bus: uart8-bus-pins {
		samsung,pins = "gpe1-7", "gpe1-6", "gpe1-5", "gpe1-4";
		samsung,pin-function = <EXYNOS_PIN_FUNC_2>;
		samsung,pin-pud = <EXYNOS_PIN_PULL_NONE>;
	};

	uart8_bus_dual: uart8-bus-dual-pins {
		samsung,pins = "gpe1-5", "gpe1-4";
		samsung,pin-function = <EXYNOS_PIN_FUNC_2>;
		samsung,pin-pud = <EXYNOS_PIN_PULL_NONE>;
	};

	uart9_bus: uart9-bus-pins {
		samsung,pins = "gpe2-3", "gpe2-2", "gpe2-1", "gpe2-0";
		samsung,pin-function = <EXYNOS_PIN_FUNC_2>;
		samsung,pin-pud = <EXYNOS_PIN_PULL_NONE>;
	};

	uart9_bus_dual: uart9-bus-dual-pins {
		samsung,pins = "gpe2-1", "gpe2-0";
		samsung,pin-function = <EXYNOS_PIN_FUNC_2>;
		samsung,pin-pud = <EXYNOS_PIN_PULL_NONE>;
	};

	uart10_bus: uart10-bus-pins {
		samsung,pins = "gpe2-7", "gpe2-6", "gpe2-5", "gpe2-4";
		samsung,pin-function = <EXYNOS_PIN_FUNC_2>;
		samsung,pin-pud = <EXYNOS_PIN_PULL_NONE>;
	};

	uart10_bus_dual: uart10-bus-dual-pins {
		samsung,pins = "gpe2-5", "gpe2-4";
		samsung,pin-function = <EXYNOS_PIN_FUNC_2>;
		samsung,pin-pud = <EXYNOS_PIN_PULL_NONE>;
	};

	uart11_bus: uart11-bus-pins {
		samsung,pins = "gpe3-3", "gpe3-2", "gpe3-1", "gpe3-0";
		samsung,pin-function = <EXYNOS_PIN_FUNC_2>;
		samsung,pin-pud = <EXYNOS_PIN_PULL_NONE>;
	};

	uart11_bus_dual: uart11-bus-dual-pins {
		samsung,pins = "gpe3-1", "gpe3-0";
		samsung,pin-function = <EXYNOS_PIN_FUNC_2>;
		samsung,pin-pud = <EXYNOS_PIN_PULL_NONE>;
	};

	uart12_bus: uart12-bus-pins {
		samsung,pins = "gpe3-7", "gpe3-6", "gpe3-5", "gpe3-4";
		samsung,pin-function = <EXYNOS_PIN_FUNC_2>;
		samsung,pin-pud = <EXYNOS_PIN_PULL_NONE>;
	};

	uart12_bus_dual: uart12-bus-dual-pins {
		samsung,pins = "gpe3-5", "gpe3-4";
		samsung,pin-function = <EXYNOS_PIN_FUNC_2>;
		samsung,pin-pud = <EXYNOS_PIN_PULL_NONE>;
	};

	uart13_bus: uart13-bus-pins {
		samsung,pins = "gpe4-3", "gpe4-2", "gpe4-1", "gpe4-0";
		samsung,pin-function = <EXYNOS_PIN_FUNC_2>;
		samsung,pin-pud = <EXYNOS_PIN_PULL_NONE>;
	};

	uart13_bus_dual: uart13-bus-dual-pins {
		samsung,pins = "gpe4-1", "gpe4-0";
		samsung,pin-function = <EXYNOS_PIN_FUNC_2>;
		samsung,pin-pud = <EXYNOS_PIN_PULL_NONE>;
	};

	uart14_bus: uart14-bus-pins {
		samsung,pins = "gpe4-7", "gpe4-6", "gpe4-5", "gpe4-4";
		samsung,pin-function = <EXYNOS_PIN_FUNC_2>;
		samsung,pin-pud = <EXYNOS_PIN_PULL_NONE>;
	};

	uart14_bus_dual: uart14-bus-dual-pins {
		samsung,pins = "gpe4-5", "gpe4-4";
		samsung,pin-function = <EXYNOS_PIN_FUNC_2>;
		samsung,pin-pud = <EXYNOS_PIN_PULL_NONE>;
	};

	uart15_bus: uart15-bus-pins {
		samsung,pins = "gpe5-7", "gpe5-6", "gpe5-5", "gpe5-4";
		samsung,pin-function = <EXYNOS_PIN_FUNC_2>;
		samsung,pin-pud = <EXYNOS_PIN_PULL_NONE>;
	};

	uart15_bus_dual: uart15-bus-dual-pins {
		samsung,pins = "gpe5-5", "gpe5-4";
		samsung,pin-function = <EXYNOS_PIN_FUNC_2>;
		samsung,pin-pud = <EXYNOS_PIN_PULL_NONE>;
	};
};

&pinctrl_vts {
	gph2: gph2-gpio-bank {
		gpio-controller;
		#gpio-cells = <2>;

		interrupt-controller;
		#interrupt-cells = <2>;
	};
};
